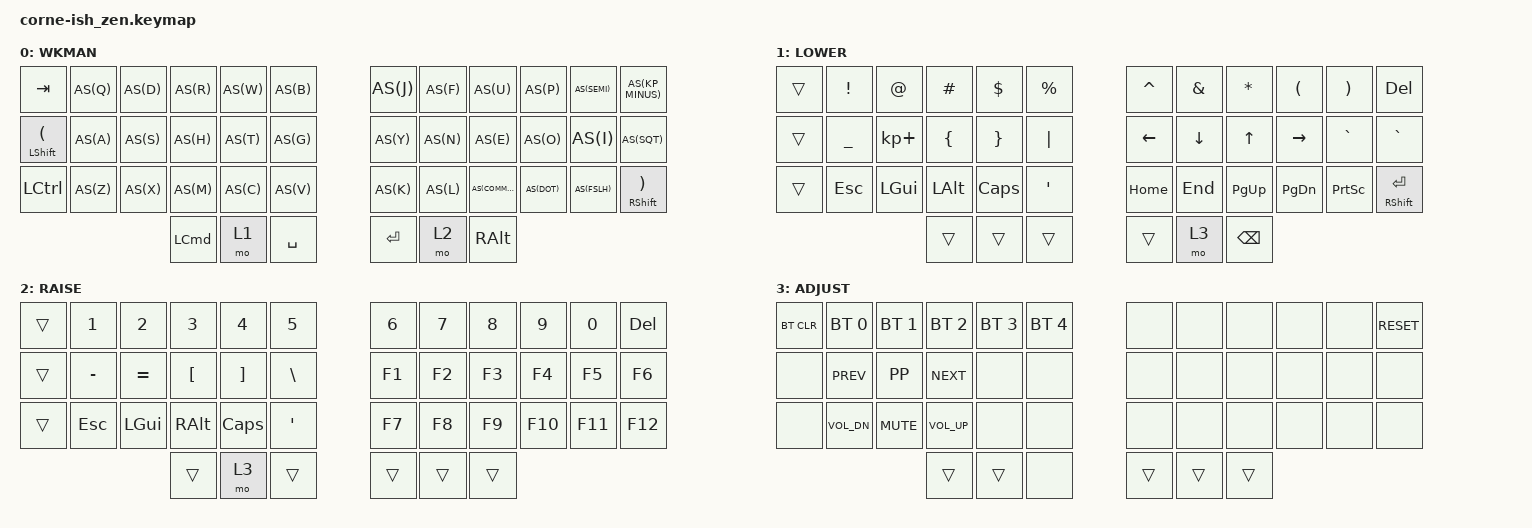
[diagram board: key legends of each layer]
/*
 * Copyright (c) 2020 The ZMK Contributors
 *
 * SPDX-License-Identifier: MIT
 */

#include <behaviors.dtsi>
#include <dt-bindings/zmk/keys.h>
#include <dt-bindings/zmk/bt.h>

#define AS(keycode) &as LS(keycode) keycode
#define WKMAN 0
#define LOWER 1
#define RAISE 2
#define ADJUST 3

/ {
        behaviors {
            as: auto_shift {
                compatible = "zmk,behavior-hold-tap";
                label = "AUTO_SHIFT";
                #binding-cells = <2>;
                tapping_term_ms = <150>;
                quick_tap_ms = <0>;
                flavor = "tap-preferred";
                bindings = <&kp>, <&kp>;
            };
        };

        keymap {
                compatible = "zmk,keymap";

                default_layer {
// -------------------------------------------------------------------------------------
// | TAB         |  Q  |  D  |  R  |  W  |  B  |   |  J  |  F   |  U  |  P  |  ;  |    -      |
// | (SHFT       |  A  |  S  |  H  |  T  |  G  |   |  Y  |  N   |  E  |  O  |  i  |    '      |
// | CTRL        |  Z  |  X  |  M  |  C  |  V  |   |  K  |  L   |  ,  |  .  |  /  |   SHFT)   |
//                      | ALT | LWR | SPC |   | ENT | RSE  | ALT |
                        label = "WKMAN";
                        bindings = <
   &kp TAB         AS(Q) AS(D) AS(R) AS(W) AS(B)   AS(J) AS(F)  AS(U)     AS(P)   AS(SEMI)    AS(KP_MINUS)
   &mt LSHFT LPAR  AS(A) AS(S) AS(H) AS(T) AS(G)   AS(Y) AS(N)  AS(E)     AS(O)   AS(I)       AS(SQT)
   &kp LCTRL       AS(Z) AS(X) AS(M) AS(C) AS(V)   AS(K) AS(L)  AS(COMMA) AS(DOT) AS(FSLH) &mt RSHFT RPAR
                               &kp LCMD  &mo 1 &kp SPACE &kp RET &mo 2  &kp RALT
                        >;
                };

                lower_layer {
// ----------------------------------------------------------------------------------
// |    |  !  |  @  |  #  |  $  |  %  |   |  ^  |  &  |  *  |  (  |  )  |    DEL    |
// |    |  _  |  +  |  {  |  }  | "|" |   | LFT | DWN |  UP | RGT |  `  |     ~     |
// |    | ESC | GUI | ALT | CAPS|  "  |   | HOME| END | PGUP| PGDN| PRSC| SHFT(RET) |
//                       |     |     | RET | ADJ |     |
                        label = "LOWER";
                        bindings = <
   &trans &kp EXCL  &kp AT      &kp HASH &kp DLLR &kp PRCNT      &kp CARET &kp AMPS &kp ASTRK &kp LPAR  &kp RPAR  &kp DEL
   &trans &kp UNDER &kp KP_PLUS &kp LBRC &kp RBRC &kp PIPE       &kp LEFT  &kp DOWN &kp UP    &kp RIGHT &kp GRAVE &kp GRAVE
   &trans &kp ESC   &kp LGUI    &kp LALT &kp CLCK &kp SQT        &kp HOME  &kp END  &kp PG_UP &kp PG_DN &kp PSCRN &mt RSHFT RET
                                &trans   &trans   &trans         &trans    &mo 3    &kp BSPC
                        >;
                };

                raise_layer {
// -----------------------------------------------------------------------------------------
// |    |  1  |  2  |  3  |  4  |  5  |   |  6  |  7  |  8  |  9  |  0  | DEL |
// |    |  -  |  =  |  [  |  ]  |  \  |   | F1  | F2  | F3  | F4  | F5  | F6  |
// |    | ESC | GUI | ALT | CAPS|  "  |   | F7  | F8  | F9  | F10 | F11 | F12 |
//                       |     | ADJ | BKSP |    |     |
                        label = "RAISE";
                        bindings = <
   &trans &kp N1    &kp N2    &kp N3    &kp N4    &kp N5        &kp N6    &kp N7    &kp N8    &kp N9    &kp N0    &kp DEL
   &trans &kp MINUS &kp EQUAL &kp LBKT  &kp RBKT  &kp BSLH      &kp F1    &kp F2    &kp F3    &kp F4    &kp F5    &kp F6
   &trans &kp ESC   &kp LGUI  &kp RALT  &kp CLCK  &kp SQT       &kp F7    &kp F8    &kp F9    &kp F10   &kp F11   &kp F12
                              &trans    &mo 3     &trans        &trans    &trans    &trans
                        >;
                };

                adjust_layer {
// -----------------------------------------------------------------------------------------
// | BTCLR| BT0      | BT1    | BT2      | BT3   | BT4 |       | RGB TOG  |          |          |          |  | RESET  |
// |      | K_PREV   | K_PP   | K_NEXT   |       |     |       | RGB ANI+ | RGB SAT+ | RGB HUE+ | RGB BRI+ |  |        |
// |      | K_VOL_DN | K_MUTE | K_VOL_UP |       |     |       | RGB ANI- | RGB SAT- | RGB HUE- | RGB BRI+ |  |        |
//                            |          |       |     |       |          |          |          |

                        label = "ADJUST";
                        bindings = <
    &bt BT_CLR &bt BT_SEL 0 &bt BT_SEL 1 &bt BT_SEL 2 &bt BT_SEL 3 &bt BT_SEL 4      &none  &none  &none  &none  &none  &kp C_RESET
    &none      &kp K_PREV   &kp K_PP     &kp K_NEXT   &none        &none             &none  &none  &none  &none  &none  &none
    &none      &kp K_VOL_DN &kp K_MUTE   &kp K_VOL_UP &none        &none             &none  &none  &none  &none  &none  &none
                                         &trans       &trans       &none            &trans &trans &trans
                        >;
                };
        };
};
